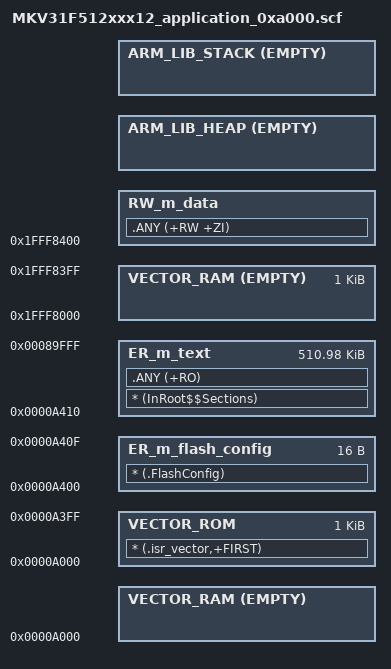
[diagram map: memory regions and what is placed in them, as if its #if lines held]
#!armclang --target=arm-arm-none-eabi -mcpu=cortex-m4 -E -x c
/*
** ###################################################################
**     Processors:          MKV31F512VLH12
**                          MKV31F512VLL12
**
**     Compiler:            Keil ARM C/C++ Compiler
**
**     Abstract:
**         Linker file for the Keil ARM C/C++ Compiler
**
**     Copyright (c) 2015 Freescale Semiconductor, Inc.
**     Copyright 2016-2018 NXP
**     All rights reserved.
**
**     SPDX-License-Identifier: BSD-3-Clause
**
**     http:                 www.nxp.com
**     mail:                 support@nxp.com
**
** ###################################################################
*/

#if (defined(__ram_vector_table__))
  #define __ram_vector_table_size__    0x00000400
#else
  #define __ram_vector_table_size__    0x00000000
#endif

#define m_interrupts_start             0x0000a000
#define m_interrupts_size              0x00000400

#define m_flash_config_start           0x0000a400
#define m_flash_config_size            0x00000010

#define m_text_start                   0x0000a410
#define m_text_size                    0x0007FBF0

#define m_interrupts_ram_start         0x1FFF8000
#define m_interrupts_ram_size          __ram_vector_table_size__

#define m_data_start                   (m_interrupts_ram_start + m_interrupts_ram_size)
#define m_data_size                    (0x00008000 - m_interrupts_ram_size)

#define m_data_2_start                 0x20000000
#define m_data_2_size                  0x00010000

/* Sizes */
#if (defined(__stack_size__))
  #define Stack_Size                   __stack_size__
#else
  #define Stack_Size                   0x0200
#endif

#if (defined(__heap_size__))
  #define Heap_Size                    __heap_size__
#else
  #define Heap_Size                    0x0
#endif

LR_m_text m_text_start m_text_size {   ; load region size_region
  ER_m_text m_text_start m_text_size { ; load address = execution address
    * (InRoot$$Sections)
    .ANY (+RO)
  }
  RW_m_data m_data_start m_data_size +  m_data_2_size-Stack_Size-Heap_Size{ ; RW data
    .ANY (+RW +ZI)
  }
  ARM_LIB_HEAP (ImageLimit(RW_m_data)) EMPTY Heap_Size { ; Heap region growing up
  }
  ARM_LIB_STACK (ImageLimit(ARM_LIB_HEAP) + Stack_Size) EMPTY -Stack_Size { ; Stack region growing down
  }
}

LR_m_interrupts m_interrupts_start m_interrupts_size {
#if (!defined(__ram_vector_table__))
  VECTOR_RAM m_interrupts_start EMPTY 0 {
  }
#endif
  VECTOR_ROM m_interrupts_start m_interrupts_size { ; load address = execution address
    * (.isr_vector,+FIRST)
  }
}

LR_m_flash_config m_flash_config_start m_flash_config_size {
  ER_m_flash_config m_flash_config_start m_flash_config_size { ; load address = execution address
    * (.FlashConfig)
  }
}

#if (defined(__ram_vector_table__))
LR_m_interrupts_ram m_interrupts_ram_start m_interrupts_ram_size {
  VECTOR_RAM m_interrupts_ram_start EMPTY m_interrupts_ram_size {
  }
}
#endif

